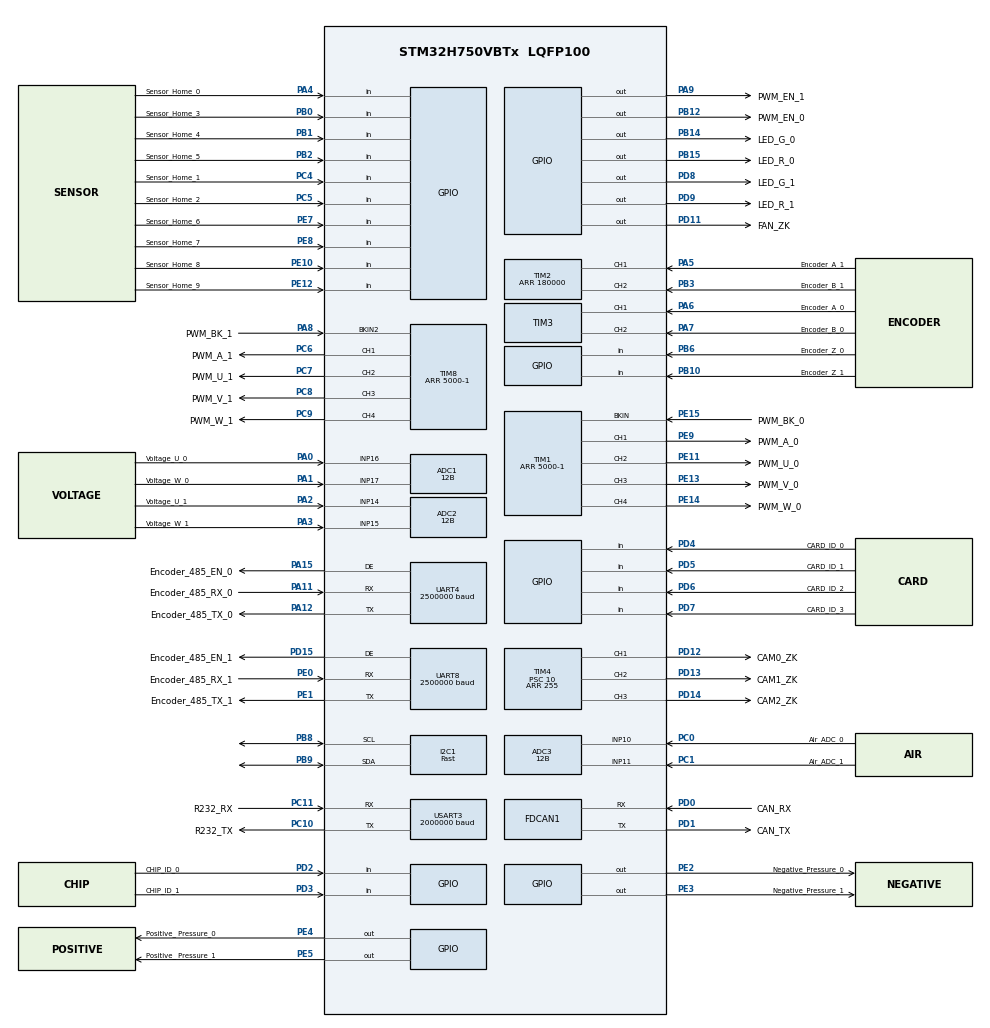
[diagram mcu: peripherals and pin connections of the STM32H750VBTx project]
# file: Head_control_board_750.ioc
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ADC1.EOCSelection=ADC_EOC_SEQ_CONV
ADC1.EnableInjectedConversion=ENABLE
ADC1.EnableRegularConversion=DISABLE
ADC1.ExternalTrigInjecConv=ADC_EXTERNALTRIGINJEC_T1_TRGO
ADC1.InjNumberOfConversion=2
ADC1.InjectedChannel-2\#ChannelInjectedConversion=ADC_CHANNEL_16
ADC1.InjectedChannel-3\#ChannelInjectedConversion=ADC_CHANNEL_17
ADC1.InjectedOffsetNumber-2\#ChannelInjectedConversion=ADC_OFFSET_NONE
ADC1.InjectedOffsetNumber-3\#ChannelInjectedConversion=ADC_OFFSET_NONE
ADC1.InjectedOffsetSaturation-2\#ChannelInjectedConversion=DISABLE
ADC1.InjectedOffsetSaturation-3\#ChannelInjectedConversion=DISABLE
ADC1.InjectedRank-2\#ChannelInjectedConversion=1
ADC1.InjectedRank-3\#ChannelInjectedConversion=2
ADC1.InjectedSamplingTime-2\#ChannelInjectedConversion=ADC_SAMPLETIME_2CYCLES_5
ADC1.InjectedSamplingTime-3\#ChannelInjectedConversion=ADC_SAMPLETIME_2CYCLES_5
ADC1.Resolution=ADC_RESOLUTION_12B
ADC1.master=1
ADC2.EOCSelection=ADC_EOC_SEQ_CONV
ADC2.EnableInjectedConversion=ENABLE
ADC2.EnableRegularConversion=DISABLE
ADC2.ExternalTrigInjecConv=ADC_EXTERNALTRIGINJEC_T8_TRGO
ADC2.InjNumberOfConversion=2
ADC2.InjectedChannel-3\#ChannelInjectedConversion=ADC_CHANNEL_14
ADC2.InjectedChannel-4\#ChannelInjectedConversion=ADC_CHANNEL_15
ADC2.InjectedOffsetNumber-3\#ChannelInjectedConversion=ADC_OFFSET_NONE
ADC2.InjectedOffsetNumber-4\#ChannelInjectedConversion=ADC_OFFSET_NONE
ADC2.InjectedOffsetSaturation-3\#ChannelInjectedConversion=DISABLE
ADC2.InjectedOffsetSaturation-4\#ChannelInjectedConversion=DISABLE
ADC2.InjectedRank-3\#ChannelInjectedConversion=1
ADC2.InjectedRank-4\#ChannelInjectedConversion=2
ADC2.InjectedSamplingTime-3\#ChannelInjectedConversion=ADC_SAMPLETIME_2CYCLES_5
ADC2.InjectedSamplingTime-4\#ChannelInjectedConversion=ADC_SAMPLETIME_2CYCLES_5
ADC2.Resolution=ADC_RESOLUTION_12B
ADC3.Channel-5\#ChannelRegularConversion=ADC_CHANNEL_10
ADC3.Channel-6\#ChannelRegularConversion=ADC_CHANNEL_11
ADC3.Channel-7\#ChannelRegularConversion=ADC_CHANNEL_TEMPSENSOR
ADC3.ContinuousConvMode=ENABLE
ADC3.ConversionDataManagement=ADC_CONVERSIONDATA_DMA_CIRCULAR
ADC3.EOCSelection=ADC_EOC_SEQ_CONV
ADC3.EnableInjectedConversion=DISABLE
ADC3.EnableRegularConversion=ENABLE
ADC3.NbrOfConversion=3
ADC3.NbrOfConversionFlag=1
ADC3.OffsetNumber-5\#ChannelRegularConversion=ADC_OFFSET_NONE
ADC3.OffsetNumber-6\#ChannelRegularConversion=ADC_OFFSET_NONE
ADC3.OffsetNumber-7\#ChannelRegularConversion=ADC_OFFSET_NONE
ADC3.Rank-5\#ChannelRegularConversion=1
ADC3.Rank-6\#ChannelRegularConversion=2
ADC3.Rank-7\#ChannelRegularConversion=3
ADC3.Resolution=ADC_RESOLUTION_12B
ADC3.SamplingTime-5\#ChannelRegularConversion=ADC_SAMPLETIME_32CYCLES_5
ADC3.SamplingTime-6\#ChannelRegularConversion=ADC_SAMPLETIME_32CYCLES_5
ADC3.SamplingTime-7\#ChannelRegularConversion=ADC_SAMPLETIME_32CYCLES_5
CORTEX_M7.default_mode_Activation=1
Dma.ADC1.3.Direction=DMA_PERIPH_TO_MEMORY
Dma.ADC1.3.EventEnable=DISABLE
Dma.ADC1.3.FIFOMode=DMA_FIFOMODE_DISABLE
Dma.ADC1.3.Instance=DMA1_Stream0
Dma.ADC1.3.MemDataAlignment=DMA_MDATAALIGN_WORD
Dma.ADC1.3.MemInc=DMA_MINC_ENABLE
Dma.ADC1.3.Mode=DMA_CIRCULAR
Dma.ADC1.3.PeriphDataAlignment=DMA_PDATAALIGN_WORD
Dma.ADC1.3.PeriphInc=DMA_PINC_DISABLE
Dma.ADC1.3.Polarity=HAL_DMAMUX_REQ_GEN_RISING
Dma.ADC1.3.Priority=DMA_PRIORITY_LOW
Dma.ADC1.3.RequestNumber=1
Dma.ADC1.3.SignalID=NONE
Dma.ADC1.3.SyncEnable=DISABLE
Dma.ADC1.3.SyncPolarity=HAL_DMAMUX_SYNC_NO_EVENT
Dma.ADC1.3.SyncRequestNumber=1
Dma.ADC1.3.SyncSignalID=NONE
Dma.ADC2.4.Direction=DMA_PERIPH_TO_MEMORY
Dma.ADC2.4.EventEnable=DISABLE
Dma.ADC2.4.FIFOMode=DMA_FIFOMODE_DISABLE
Dma.ADC2.4.Instance=DMA2_Stream0
Dma.ADC2.4.MemDataAlignment=DMA_MDATAALIGN_WORD
Dma.ADC2.4.MemInc=DMA_MINC_ENABLE
Dma.ADC2.4.Mode=DMA_CIRCULAR
Dma.ADC2.4.PeriphDataAlignment=DMA_PDATAALIGN_WORD
Dma.ADC2.4.PeriphInc=DMA_PINC_DISABLE
Dma.ADC2.4.Polarity=HAL_DMAMUX_REQ_GEN_RISING
Dma.ADC2.4.Priority=DMA_PRIORITY_LOW
Dma.ADC2.4.RequestNumber=1
Dma.ADC2.4.SignalID=NONE
Dma.ADC2.4.SyncEnable=DISABLE
Dma.ADC2.4.SyncPolarity=HAL_DMAMUX_SYNC_NO_EVENT
Dma.ADC2.4.SyncRequestNumber=1
Dma.ADC2.4.SyncSignalID=NONE
Dma.ADC3.5.Direction=DMA_PERIPH_TO_MEMORY
Dma.ADC3.5.EventEnable=DISABLE
Dma.ADC3.5.FIFOMode=DMA_FIFOMODE_DISABLE
Dma.ADC3.5.Instance=DMA1_Stream2
Dma.ADC3.5.MemDataAlignment=DMA_MDATAALIGN_HALFWORD
Dma.ADC3.5.MemInc=DMA_MINC_ENABLE
Dma.ADC3.5.Mode=DMA_CIRCULAR
Dma.ADC3.5.PeriphDataAlignment=DMA_PDATAALIGN_HALFWORD
Dma.ADC3.5.PeriphInc=DMA_PINC_DISABLE
Dma.ADC3.5.Polarity=HAL_DMAMUX_REQ_GEN_RISING
Dma.ADC3.5.Priority=DMA_PRIORITY_LOW
Dma.ADC3.5.RequestNumber=1
Dma.ADC3.5.SignalID=NONE
Dma.ADC3.5.SyncEnable=DISABLE
Dma.ADC3.5.SyncPolarity=HAL_DMAMUX_SYNC_NO_EVENT
Dma.ADC3.5.SyncRequestNumber=1
Dma.ADC3.5.SyncSignalID=NONE
Dma.I2C1_RX.9.Direction=DMA_PERIPH_TO_MEMORY
Dma.I2C1_RX.9.EventEnable=DISABLE
Dma.I2C1_RX.9.FIFOMode=DMA_FIFOMODE_DISABLE
Dma.I2C1_RX.9.Instance=DMA1_Stream7
Dma.I2C1_RX.9.MemDataAlignment=DMA_MDATAALIGN_BYTE
Dma.I2C1_RX.9.MemInc=DMA_MINC_ENABLE
Dma.I2C1_RX.9.Mode=DMA_NORMAL
Dma.I2C1_RX.9.PeriphDataAlignment=DMA_PDATAALIGN_BYTE
Dma.I2C1_RX.9.PeriphInc=DMA_PINC_DISABLE
Dma.I2C1_RX.9.Polarity=HAL_DMAMUX_REQ_GEN_RISING
Dma.I2C1_RX.9.Priority=DMA_PRIORITY_LOW
Dma.I2C1_RX.9.RequestNumber=1
Dma.I2C1_RX.9.SignalID=NONE
Dma.I2C1_RX.9.SyncEnable=DISABLE
Dma.I2C1_RX.9.SyncPolarity=HAL_DMAMUX_SYNC_NO_EVENT
Dma.I2C1_RX.9.SyncRequestNumber=1
Dma.I2C1_RX.9.SyncSignalID=NONE
Dma.I2C1_TX.10.Direction=DMA_MEMORY_TO_PERIPH
Dma.I2C1_TX.10.EventEnable=DISABLE
Dma.I2C1_TX.10.FIFOMode=DMA_FIFOMODE_DISABLE
Dma.I2C1_TX.10.Instance=DMA2_Stream1
Dma.I2C1_TX.10.MemDataAlignment=DMA_MDATAALIGN_BYTE
Dma.I2C1_TX.10.MemInc=DMA_MINC_ENABLE
Dma.I2C1_TX.10.Mode=DMA_NORMAL
Dma.I2C1_TX.10.PeriphDataAlignment=DMA_PDATAALIGN_BYTE
Dma.I2C1_TX.10.PeriphInc=DMA_PINC_DISABLE
Dma.I2C1_TX.10.Polarity=HAL_DMAMUX_REQ_GEN_RISING
Dma.I2C1_TX.10.Priority=DMA_PRIORITY_LOW
Dma.I2C1_TX.10.RequestNumber=1
Dma.I2C1_TX.10.SignalID=NONE
Dma.I2C1_TX.10.SyncEnable=DISABLE
Dma.I2C1_TX.10.SyncPolarity=HAL_DMAMUX_SYNC_NO_EVENT
Dma.I2C1_TX.10.SyncRequestNumber=1
Dma.I2C1_TX.10.SyncSignalID=NONE
Dma.Request0=USART3_RX
Dma.Request1=USART3_TX
Dma.Request10=I2C1_TX
Dma.Request2=UART4_RX
Dma.Request3=ADC1
Dma.Request4=ADC2
Dma.Request5=ADC3
Dma.Request6=UART4_TX
Dma.Request7=UART8_RX
Dma.Request8=UART8_TX
Dma.Request9=I2C1_RX
Dma.UART4_RX.2.Direction=DMA_PERIPH_TO_MEMORY
Dma.UART4_RX.2.EventEnable=DISABLE
Dma.UART4_RX.2.FIFOMode=DMA_FIFOMODE_DISABLE
Dma.UART4_RX.2.Instance=DMA2_Stream4
Dma.UART4_RX.2.MemDataAlignment=DMA_MDATAALIGN_BYTE
Dma.UART4_RX.2.MemInc=DMA_MINC_ENABLE
Dma.UART4_RX.2.Mode=DMA_NORMAL
Dma.UART4_RX.2.PeriphDataAlignment=DMA_PDATAALIGN_BYTE
Dma.UART4_RX.2.PeriphInc=DMA_PINC_DISABLE
Dma.UART4_RX.2.Polarity=HAL_DMAMUX_REQ_GEN_RISING
Dma.UART4_RX.2.Priority=DMA_PRIORITY_LOW
Dma.UART4_RX.2.RequestNumber=1
Dma.UART4_RX.2.SignalID=NONE
Dma.UART4_RX.2.SyncEnable=DISABLE
Dma.UART4_RX.2.SyncPolarity=HAL_DMAMUX_SYNC_NO_EVENT
Dma.UART4_RX.2.SyncRequestNumber=1
Dma.UART4_RX.2.SyncSignalID=NONE
Dma.UART4_TX.6.Direction=DMA_MEMORY_TO_PERIPH
Dma.UART4_TX.6.EventEnable=DISABLE
Dma.UART4_TX.6.FIFOMode=DMA_FIFOMODE_DISABLE
Dma.UART4_TX.6.Instance=DMA1_Stream4
Dma.UART4_TX.6.MemDataAlignment=DMA_MDATAALIGN_BYTE
Dma.UART4_TX.6.MemInc=DMA_MINC_ENABLE
Dma.UART4_TX.6.Mode=DMA_NORMAL
Dma.UART4_TX.6.PeriphDataAlignment=DMA_PDATAALIGN_BYTE
Dma.UART4_TX.6.PeriphInc=DMA_PINC_DISABLE
Dma.UART4_TX.6.Polarity=HAL_DMAMUX_REQ_GEN_RISING
Dma.UART4_TX.6.Priority=DMA_PRIORITY_LOW
Dma.UART4_TX.6.RequestNumber=1
Dma.UART4_TX.6.SignalID=NONE
Dma.UART4_TX.6.SyncEnable=DISABLE
Dma.UART4_TX.6.SyncPolarity=HAL_DMAMUX_SYNC_NO_EVENT
Dma.UART4_TX.6.SyncRequestNumber=1
Dma.UART4_TX.6.SyncSignalID=NONE
Dma.UART8_RX.7.Direction=DMA_PERIPH_TO_MEMORY
Dma.UART8_RX.7.EventEnable=DISABLE
Dma.UART8_RX.7.FIFOMode=DMA_FIFOMODE_DISABLE
Dma.UART8_RX.7.Instance=DMA1_Stream5
Dma.UART8_RX.7.MemDataAlignment=DMA_MDATAALIGN_BYTE
Dma.UART8_RX.7.MemInc=DMA_MINC_ENABLE
Dma.UART8_RX.7.Mode=DMA_NORMAL
Dma.UART8_RX.7.PeriphDataAlignment=DMA_PDATAALIGN_BYTE
Dma.UART8_RX.7.PeriphInc=DMA_PINC_DISABLE
Dma.UART8_RX.7.Polarity=HAL_DMAMUX_REQ_GEN_RISING
Dma.UART8_RX.7.Priority=DMA_PRIORITY_LOW
Dma.UART8_RX.7.RequestNumber=1
Dma.UART8_RX.7.SignalID=NONE
Dma.UART8_RX.7.SyncEnable=DISABLE
Dma.UART8_RX.7.SyncPolarity=HAL_DMAMUX_SYNC_NO_EVENT
Dma.UART8_RX.7.SyncRequestNumber=1
Dma.UART8_RX.7.SyncSignalID=NONE
Dma.UART8_TX.8.Direction=DMA_MEMORY_TO_PERIPH
Dma.UART8_TX.8.EventEnable=DISABLE
Dma.UART8_TX.8.FIFOMode=DMA_FIFOMODE_DISABLE
Dma.UART8_TX.8.Instance=DMA1_Stream6
Dma.UART8_TX.8.MemDataAlignment=DMA_MDATAALIGN_BYTE
Dma.UART8_TX.8.MemInc=DMA_MINC_ENABLE
Dma.UART8_TX.8.Mode=DMA_NORMAL
Dma.UART8_TX.8.PeriphDataAlignment=DMA_PDATAALIGN_BYTE
Dma.UART8_TX.8.PeriphInc=DMA_PINC_DISABLE
Dma.UART8_TX.8.Polarity=HAL_DMAMUX_REQ_GEN_RISING
Dma.UART8_TX.8.Priority=DMA_PRIORITY_LOW
Dma.UART8_TX.8.RequestNumber=1
Dma.UART8_TX.8.SignalID=NONE
Dma.UART8_TX.8.SyncEnable=DISABLE
Dma.UART8_TX.8.SyncPolarity=HAL_DMAMUX_SYNC_NO_EVENT
Dma.UART8_TX.8.SyncRequestNumber=1
Dma.UART8_TX.8.SyncSignalID=NONE
Dma.USART3_RX.0.Direction=DMA_PERIPH_TO_MEMORY
Dma.USART3_RX.0.EventEnable=DISABLE
Dma.USART3_RX.0.FIFOMode=DMA_FIFOMODE_DISABLE
Dma.USART3_RX.0.Instance=DMA1_Stream1
Dma.USART3_RX.0.MemDataAlignment=DMA_MDATAALIGN_BYTE
Dma.USART3_RX.0.MemInc=DMA_MINC_ENABLE
Dma.USART3_RX.0.Mode=DMA_NORMAL
Dma.USART3_RX.0.PeriphDataAlignment=DMA_PDATAALIGN_BYTE
Dma.USART3_RX.0.PeriphInc=DMA_PINC_DISABLE
Dma.USART3_RX.0.Polarity=HAL_DMAMUX_REQ_GEN_RISING
Dma.USART3_RX.0.Priority=DMA_PRIORITY_LOW
Dma.USART3_RX.0.RequestNumber=1
Dma.USART3_RX.0.SignalID=NONE
Dma.USART3_RX.0.SyncEnable=DISABLE
Dma.USART3_RX.0.SyncPolarity=HAL_DMAMUX_SYNC_NO_EVENT
Dma.USART3_RX.0.SyncRequestNumber=1
Dma.USART3_RX.0.SyncSignalID=NONE
Dma.USART3_TX.1.Direction=DMA_MEMORY_TO_PERIPH
Dma.USART3_TX.1.EventEnable=DISABLE
Dma.USART3_TX.1.FIFOMode=DMA_FIFOMODE_DISABLE
Dma.USART3_TX.1.Instance=DMA1_Stream3
Dma.USART3_TX.1.MemDataAlignment=DMA_MDATAALIGN_BYTE
Dma.USART3_TX.1.MemInc=DMA_MINC_ENABLE
Dma.USART3_TX.1.Mode=DMA_NORMAL
Dma.USART3_TX.1.PeriphDataAlignment=DMA_PDATAALIGN_BYTE
Dma.USART3_TX.1.PeriphInc=DMA_PINC_DISABLE
Dma.USART3_TX.1.Polarity=HAL_DMAMUX_REQ_GEN_RISING
Dma.USART3_TX.1.Priority=DMA_PRIORITY_LOW
Dma.USART3_TX.1.RequestNumber=1
Dma.USART3_TX.1.SignalID=NONE
Dma.USART3_TX.1.SyncEnable=DISABLE
Dma.USART3_TX.1.SyncPolarity=HAL_DMAMUX_SYNC_NO_EVENT
Dma.USART3_TX.1.SyncRequestNumber=1
Dma.USART3_TX.1.SyncSignalID=NONE
FDCAN1.CalculateBaudRateNominal=1000000
FDCAN1.CalculateTimeBitNominal=1000
FDCAN1.CalculateTimeQuantumNominal=100.0
FDCAN1.ExtFiltersNbr=1
FDCAN1.NominalPrescaler=10
FDCAN1.NominalSyncJumpWidth=3
FDCAN1.NominalTimeSeg1=6
FDCAN1.NominalTimeSeg2=3
FDCAN1.RxFifo0ElmtsNbr=1
FDCAN1.TxFifoQueueElmtsNbr=1
I2C1.I2C_Speed_Mode=I2C_Fast
I2C1.Timing=0x009034B6
Mcu.Family=STM32H7
Mcu.Name=STM32H750VBTx
Mcu.Package=LQFP100
NVIC.ADC3_IRQn=true\:0\:0\:false\:false\:true\:true\:true\:true
NVIC.ADC_IRQn=true\:0\:0\:false\:false\:true\:true\:true\:true
NVIC.DMA1_Stream0_IRQn=true\:0\:0\:false\:false\:true\:false\:true\:true
NVIC.DMA1_Stream1_IRQn=true\:0\:0\:false\:false\:true\:false\:true\:true
NVIC.DMA1_Stream2_IRQn=true\:1\:0\:true\:false\:true\:false\:true\:true
NVIC.DMA1_Stream3_IRQn=true\:0\:0\:false\:false\:true\:false\:true\:true
NVIC.DMA1_Stream4_IRQn=true\:0\:0\:false\:false\:true\:false\:true\:true
NVIC.DMA1_Stream5_IRQn=true\:0\:0\:false\:false\:true\:false\:true\:true
NVIC.DMA1_Stream6_IRQn=true\:0\:0\:false\:false\:true\:false\:true\:true
NVIC.DMA1_Stream7_IRQn=true\:0\:0\:false\:false\:true\:false\:true\:true
NVIC.DMA2_Stream0_IRQn=true\:0\:0\:false\:false\:true\:false\:true\:true
NVIC.DMA2_Stream1_IRQn=true\:0\:0\:false\:false\:true\:false\:true\:true
NVIC.DMA2_Stream4_IRQn=true\:0\:0\:false\:false\:true\:false\:true\:true
NVIC.FDCAN1_IT0_IRQn=true\:0\:0\:false\:false\:true\:true\:true\:true
NVIC.PriorityGroup=NVIC_PRIORITYGROUP_4
NVIC.TIM1_BRK_IRQn=true\:0\:0\:false\:false\:true\:true\:true\:true
NVIC.TIM1_UP_IRQn=true\:0\:0\:false\:false\:true\:true\:true\:true
NVIC.TIM2_IRQn=true\:0\:0\:false\:false\:true\:true\:true\:true
NVIC.TIM3_IRQn=true\:0\:0\:false\:false\:true\:true\:true\:true
NVIC.TIM8_BRK_TIM12_IRQn=true\:0\:0\:false\:false\:true\:true\:true\:true
NVIC.TIM8_UP_TIM13_IRQn=true\:0\:0\:false\:false\:true\:true\:true\:true
NVIC.USART3_IRQn=true\:0\:0\:false\:false\:true\:true\:true\:true
PA0.GPIO_Label=Voltage_U_0
PA0.Mode=IN16-Single-Ended
PA0.Signal=ADC1_INP16
PA1.GPIO_Label=Voltage_W_0
PA1.Mode=IN17-Single-Ended
PA1.Signal=ADC1_INP17
PA11.GPIO_Label=Encoder_485_RX_0
PA11.GPIO_Speed=GPIO_SPEED_FREQ_VERY_HIGH
PA11.Mode=Asynchronous
PA11.Signal=UART4_RX
PA12.GPIO_Label=Encoder_485_TX_0
PA12.GPIO_Speed=GPIO_SPEED_FREQ_VERY_HIGH
PA12.Mode=Asynchronous
PA12.Signal=UART4_TX
PA13\ (JTMS/SWDIO).Mode=Serial_Wire
PA13\ (JTMS/SWDIO).Signal=DEBUG_JTMS-SWDIO
PA14\ (JTCK/SWCLK).Mode=Serial_Wire
PA14\ (JTCK/SWCLK).Signal=DEBUG_JTCK-SWCLK
PA15\ (JTDI).GPIO_Label=Encoder_485_EN_0
PA15\ (JTDI).GPIO_Speed=GPIO_SPEED_FREQ_VERY_HIGH
PA15\ (JTDI).Mode=Hardware Flow Control (RS485)
PA15\ (JTDI).Signal=UART4_DE
PA2.GPIO_Label=Voltage_U_1
PA2.Signal=ADCx_INP14
PA3.GPIO_Label=Voltage_W_1
PA3.Signal=ADCx_INP15
PA4.GPIO_Label=Sensor_Home_0
PA4.GPIO_Mode=GPIO_MODE_INPUT
PA4.GPIO_PuPd=GPIO_PULLUP
PA4.Signal=GPIO_Input
PA5.GPIO_Label=Encoder_A_1
PA5.Signal=S_TIM2_CH1_ETR
PA6.GPIO_Label=Encoder_A_0
PA6.Signal=S_TIM3_CH1
PA7.GPIO_Label=Encoder_B_0
PA7.Signal=S_TIM3_CH2
PA8.GPIO_Label=PWM_BK_1
PA8.GPIO_PuPd=GPIO_NOPULL
PA8.Mode=Activate-Break-Input-2
PA8.Signal=TIM8_BKIN2
PA9.GPIO_Label=PWM_EN_1
PA9.GPIO_ModeDefaultOutputPP=GPIO_MODE_OUTPUT_PP
PA9.GPIO_PuPd=GPIO_PULLUP
PA9.GPIO_Speed=GPIO_SPEED_FREQ_LOW
PA9.PinState=GPIO_PIN_RESET
PA9.Signal=GPIO_Output
PB0.GPIO_Label=Sensor_Home_3
PB0.GPIO_Mode=GPIO_MODE_INPUT
PB0.GPIO_PuPd=GPIO_PULLUP
PB0.Signal=GPIO_Input
PB1.GPIO_Label=Sensor_Home_4
PB1.GPIO_Mode=GPIO_MODE_INPUT
PB1.GPIO_PuPd=GPIO_PULLUP
PB1.Signal=GPIO_Input
PB10.GPIO_Label=Encoder_Z_1
PB10.GPIO_Mode=GPIO_MODE_INPUT
PB10.GPIO_PuPd=GPIO_PULLUP
PB10.Signal=GPIO_Input
PB12.GPIO_Label=PWM_EN_0
PB12.GPIO_ModeDefaultOutputPP=GPIO_MODE_OUTPUT_PP
PB12.GPIO_PuPd=GPIO_PULLUP
PB12.GPIO_Speed=GPIO_SPEED_FREQ_LOW
PB12.PinState=GPIO_PIN_RESET
PB12.Signal=GPIO_Output
PB14.GPIO_Label=LED_G_0
PB14.Signal=GPIO_Output
PB15.GPIO_Label=LED_R_0
PB15.Signal=GPIO_Output
PB2.GPIO_Label=Sensor_Home_5
PB2.GPIO_Mode=GPIO_MODE_INPUT
PB2.GPIO_PuPd=GPIO_PULLUP
PB2.Signal=GPIO_Input
PB3\ (JTDO/TRACESWO).GPIO_Label=Encoder_B_1
PB3\ (JTDO/TRACESWO).Signal=S_TIM2_CH2
PB6.GPIO_Label=Encoder_Z_0
PB6.GPIO_Mode=GPIO_MODE_INPUT
PB6.GPIO_PuPd=GPIO_PULLUP
PB6.Signal=GPIO_Input
PB8.Mode=I2C
PB8.Signal=I2C1_SCL
PB9.Mode=I2C
PB9.Signal=I2C1_SDA
PC0.GPIO_Label=Air_ADC_0
PC0.Signal=ADCx_INP10
PC1.GPIO_Label=Air_ADC_1
PC1.Signal=ADCx_INP11
PC10.GPIO_Label=R232_TX
PC10.GPIO_Speed=GPIO_SPEED_FREQ_VERY_HIGH
PC10.Mode=Asynchronous
PC10.Signal=USART3_TX
PC11.GPIO_Label=R232_RX
PC11.GPIO_Speed=GPIO_SPEED_FREQ_VERY_HIGH
PC11.Mode=Asynchronous
PC11.Signal=USART3_RX
PC4.GPIO_Label=Sensor_Home_1
PC4.GPIO_Mode=GPIO_MODE_INPUT
PC4.GPIO_PuPd=GPIO_PULLUP
PC4.Signal=GPIO_Input
PC5.GPIO_Label=Sensor_Home_2
PC5.GPIO_Mode=GPIO_MODE_INPUT
PC5.GPIO_PuPd=GPIO_PULLUP
PC5.Signal=GPIO_Input
PC6.GPIO_Label=PWM_A_1
PC6.Signal=S_TIM8_CH1
PC7.GPIO_Label=PWM_U_1
PC7.Signal=S_TIM8_CH2
PC8.GPIO_Label=PWM_V_1
PC8.Signal=S_TIM8_CH3
PC9.GPIO_Label=PWM_W_1
PC9.Signal=S_TIM8_CH4
PD0.GPIO_Label=CAN_RX
PD0.Mode=FDCAN_Activate
PD0.Signal=FDCAN1_RX
PD1.GPIO_Label=CAN_TX
PD1.Mode=FDCAN_Activate
PD1.Signal=FDCAN1_TX
PD11.GPIO_Label=FAN_ZK
PD11.GPIO_PuPd=GPIO_PULLUP
PD11.Signal=GPIO_Output
PD12.GPIO_Label=CAM0_ZK
PD12.Signal=S_TIM4_CH1
PD13.GPIO_Label=CAM1_ZK
PD13.Signal=S_TIM4_CH2
PD14.GPIO_Label=CAM2_ZK
PD14.Signal=S_TIM4_CH3
PD15.GPIO_Label=Encoder_485_EN_1
PD15.GPIO_Speed=GPIO_SPEED_FREQ_VERY_HIGH
PD15.Mode=Hardware Flow Control (RS485)
PD15.Signal=UART8_DE
PD2.GPIO_Label=CHIP_ID_0
PD2.GPIO_PuPd=GPIO_PULLUP
PD2.Signal=GPIO_Input
PD3.GPIO_Label=CHIP_ID_1
PD3.GPIO_PuPd=GPIO_PULLUP
PD3.Signal=GPIO_Input
PD4.GPIO_Label=CARD_ID_0
PD4.GPIO_PuPd=GPIO_PULLUP
PD4.Signal=GPIO_Input
PD5.GPIO_Label=CARD_ID_1
PD5.GPIO_PuPd=GPIO_PULLUP
PD5.Signal=GPIO_Input
PD6.GPIO_Label=CARD_ID_2
PD6.GPIO_PuPd=GPIO_PULLUP
PD6.Signal=GPIO_Input
PD7.GPIO_Label=CARD_ID_3
PD7.GPIO_PuPd=GPIO_PULLUP
PD7.Signal=GPIO_Input
PD8.GPIO_Label=LED_G_1
PD8.Signal=GPIO_Output
PD9.GPIO_Label=LED_R_1
PD9.GPIO_PuPd=GPIO_NOPULL
PD9.Signal=GPIO_Output
PE0.GPIO_Label=Encoder_485_RX_1
PE0.GPIO_Speed=GPIO_SPEED_FREQ_VERY_HIGH
PE0.Mode=Asynchronous
PE0.Signal=UART8_RX
PE1.GPIO_Label=Encoder_485_TX_1
PE1.GPIO_Speed=GPIO_SPEED_FREQ_VERY_HIGH
PE1.Mode=Asynchronous
PE1.Signal=UART8_TX
PE10.GPIO_Label=Sensor_Home_8
PE10.GPIO_Mode=GPIO_MODE_INPUT
PE10.GPIO_PuPd=GPIO_PULLUP
PE10.Signal=GPIO_Input
PE11.GPIO_Label=PWM_U_0
PE11.Signal=S_TIM1_CH2
PE12.GPIO_Label=Sensor_Home_9
PE12.GPIO_Mode=GPIO_MODE_INPUT
PE12.GPIO_PuPd=GPIO_PULLUP
PE12.Signal=GPIO_Input
PE13.GPIO_Label=PWM_V_0
PE13.Signal=S_TIM1_CH3
PE14.GPIO_Label=PWM_W_0
PE14.Signal=S_TIM1_CH4
PE15.GPIO_Label=PWM_BK_0
PE15.GPIO_Mode=GPIO_MODE_AF_OD
PE15.GPIO_PuPd=GPIO_NOPULL
PE15.Mode=Activate-Break-Input
PE15.Signal=TIM1_BKIN
PE2.GPIO_Label=Negative_Pressure_0
PE2.GPIO_ModeDefaultOutputPP=GPIO_MODE_OUTPUT_PP
PE2.GPIO_PuPd=GPIO_PULLUP
PE2.GPIO_Speed=GPIO_SPEED_FREQ_LOW
PE2.PinState=GPIO_PIN_RESET
PE2.Signal=GPIO_Output
PE3.GPIO_Label=Negative_Pressure_1
PE3.GPIO_ModeDefaultOutputPP=GPIO_MODE_OUTPUT_PP
PE3.GPIO_PuPd=GPIO_PULLUP
PE3.GPIO_Speed=GPIO_SPEED_FREQ_LOW
PE3.PinState=GPIO_PIN_RESET
PE3.Signal=GPIO_Output
PE4.GPIO_Label=Positive_ Pressure_0
PE4.GPIO_ModeDefaultOutputPP=GPIO_MODE_OUTPUT_PP
PE4.GPIO_PuPd=GPIO_PULLUP
PE4.GPIO_Speed=GPIO_SPEED_FREQ_LOW
PE4.PinState=GPIO_PIN_RESET
PE4.Signal=GPIO_Output
PE5.GPIO_Label=Positive_ Pressure_1
PE5.GPIO_ModeDefaultOutputPP=GPIO_MODE_OUTPUT_PP
PE5.GPIO_PuPd=GPIO_PULLUP
PE5.GPIO_Speed=GPIO_SPEED_FREQ_LOW
PE5.PinState=GPIO_PIN_RESET
PE5.Signal=GPIO_Output
PE7.GPIO_Label=Sensor_Home_6
PE7.GPIO_Mode=GPIO_MODE_INPUT
PE7.GPIO_PuPd=GPIO_PULLUP
PE7.Signal=GPIO_Input
PE8.GPIO_Label=Sensor_Home_7
PE8.GPIO_Mode=GPIO_MODE_INPUT
PE8.GPIO_PuPd=GPIO_PULLUP
PE8.Signal=GPIO_Input
PE9.GPIO_Label=PWM_A_0
PE9.Signal=S_TIM1_CH1
PH0-OSC_IN\ (PH0).Mode=HSE-External-Clock-Source
PH0-OSC_IN\ (PH0).Signal=RCC_OSC_IN
ProjectManager.HeapSize=0x200
ProjectManager.StackSize=0x400
ProjectManager.TargetToolchain=CMake
RCC.ADCFreq_Value=100000000
RCC.APB1Freq_Value=100000000
RCC.APB2Freq_Value=100000000
RCC.APB3Freq_Value=100000000
RCC.APB4Freq_Value=100000000
RCC.CortexFreq_Value=400000000
RCC.D1PPRE=RCC_APB3_DIV2
RCC.D2PPRE1=RCC_APB1_DIV2
RCC.D2PPRE2=RCC_APB2_DIV2
RCC.D3PPRE=RCC_APB4_DIV2
RCC.DIVM1=5
RCC.DIVM2=5
RCC.DIVN1=160
RCC.DIVN2=160
RCC.DIVP2=8
RCC.DIVQ1=8
RCC.HCLKFreq_Value=200000000
RCC.HPRE=RCC_HCLK_DIV2
RCC.PLLSourceVirtual=RCC_PLLSOURCE_HSE
RCC.SYSCLKFreq_VALUE=400000000
RCC.SYSCLKSource=RCC_SYSCLKSOURCE_PLLCLK
RCC.USBFreq_Value=100000000
SH.ADCx_INP10.0=ADC3_INP10,IN10-Single-Ended
SH.ADCx_INP11.0=ADC3_INP11,IN11-Single-Ended
SH.ADCx_INP14.0=ADC2_INP14,IN14-Single-Ended
SH.ADCx_INP15.0=ADC2_INP15,IN15-Single-Ended
SH.S_TIM1_CH1.0=TIM1_CH1,PWM Generation1 CH1
SH.S_TIM1_CH2.0=TIM1_CH2,PWM Generation2 CH2
SH.S_TIM1_CH3.0=TIM1_CH3,PWM Generation3 CH3
SH.S_TIM1_CH4.0=TIM1_CH4,PWM Generation4 CH4
SH.S_TIM2_CH1_ETR.0=TIM2_CH1,Encoder_Interface
SH.S_TIM2_CH2.0=TIM2_CH2,Encoder_Interface
SH.S_TIM3_CH1.0=TIM3_CH1,Encoder_Interface
SH.S_TIM3_CH2.0=TIM3_CH2,Encoder_Interface
SH.S_TIM4_CH1.0=TIM4_CH1,PWM Generation1 CH1
SH.S_TIM4_CH2.0=TIM4_CH2,PWM Generation2 CH2
SH.S_TIM4_CH3.0=TIM4_CH3,PWM Generation3 CH3
SH.S_TIM8_CH1.0=TIM8_CH1,PWM Generation1 CH1
SH.S_TIM8_CH2.0=TIM8_CH2,PWM Generation2 CH2
SH.S_TIM8_CH3.0=TIM8_CH3,PWM Generation3 CH3
SH.S_TIM8_CH4.0=TIM8_CH4,PWM Generation4 CH4
TIM1.AutoReloadPreload=TIM_AUTORELOAD_PRELOAD_ENABLE
TIM1.AutomaticOutput=TIM_AUTOMATICOUTPUT_ENABLE
TIM1.Break2Polarity=TIM_BREAK2POLARITY_HIGH
TIM1.Break2State=TIM_BREAK2_DISABLE
TIM1.BreakPolarity=TIM_BREAKPOLARITY_LOW
TIM1.BreakState=TIM_BREAK_ENABLE
TIM1.Channel-PWM\ Generation1\ CH1=TIM_CHANNEL_1
TIM1.Channel-PWM\ Generation2\ CH2=TIM_CHANNEL_2
TIM1.Channel-PWM\ Generation3\ CH3=TIM_CHANNEL_3
TIM1.Channel-PWM\ Generation4\ CH4=TIM_CHANNEL_4
TIM1.CounterMode=TIM_COUNTERMODE_CENTERALIGNED3
TIM1.OCMode_PWM-PWM\ Generation1\ CH1=TIM_OCMODE_PWM2
TIM1.OCMode_PWM-PWM\ Generation2\ CH2=TIM_OCMODE_PWM2
TIM1.OCMode_PWM-PWM\ Generation3\ CH3=TIM_OCMODE_PWM2
TIM1.OCMode_PWM-PWM\ Generation4\ CH4=TIM_OCMODE_PWM2
TIM1.OffStateIDLEMode=TIM_OSSI_DISABLE
TIM1.OffStateRunMode=TIM_OSSR_DISABLE
TIM1.Period=5000-1
TIM1.Pulse-PWM\ Generation1\ CH1=0
TIM1.Pulse-PWM\ Generation2\ CH2=0
TIM1.Pulse-PWM\ Generation3\ CH3=0
TIM1.Pulse-PWM\ Generation4\ CH4=0
TIM1.SourceBRKDigInput=TIM_BREAKINPUTSOURCE_DISABLE
TIM1.TIM_MasterOutputTrigger=TIM_TRGO_UPDATE
TIM2.EncoderMode=TIM_ENCODERMODE_TI12
TIM2.Period=180000
TIM3.EncoderMode=TIM_ENCODERMODE_TI12
TIM4.AutoReloadPreload=TIM_AUTORELOAD_PRELOAD_ENABLE
TIM4.Channel-PWM\ Generation1\ CH1=TIM_CHANNEL_1
TIM4.Channel-PWM\ Generation2\ CH2=TIM_CHANNEL_2
TIM4.Channel-PWM\ Generation3\ CH3=TIM_CHANNEL_3
TIM4.Channel-PWM\ Generation4\ CH4=TIM_CHANNEL_4
TIM4.Period=255
TIM4.Prescaler=10
TIM8.Break2Polarity=TIM_BREAK2POLARITY_LOW
TIM8.BreakPolarity=TIM_BREAKPOLARITY_HIGH
TIM8.BreakState=TIM_BREAK_DISABLE
TIM8.Channel-PWM\ Generation1\ CH1=TIM_CHANNEL_1
TIM8.Channel-PWM\ Generation2\ CH2=TIM_CHANNEL_2
TIM8.Channel-PWM\ Generation3\ CH3=TIM_CHANNEL_3
TIM8.Channel-PWM\ Generation4\ CH4=TIM_CHANNEL_4
TIM8.CounterMode=TIM_COUNTERMODE_CENTERALIGNED3
TIM8.OCMode_PWM-PWM\ Generation1\ CH1=TIM_OCMODE_PWM2
TIM8.OCMode_PWM-PWM\ Generation2\ CH2=TIM_OCMODE_PWM2
TIM8.OCMode_PWM-PWM\ Generation3\ CH3=TIM_OCMODE_PWM2
TIM8.OCMode_PWM-PWM\ Generation4\ CH4=TIM_OCMODE_PWM2
TIM8.Period=5000-1
TIM8.Pulse-PWM\ Generation1\ CH1=0
TIM8.Pulse-PWM\ Generation2\ CH2=0
TIM8.Pulse-PWM\ Generation3\ CH3=0
TIM8.Pulse-PWM\ Generation4\ CH4=0
TIM8.SourceBRK2DigInputPolarity=TIM_BREAKINPUTSOURCE_POLARITY_LOW
TIM8.TIM_MasterOutputTrigger=TIM_TRGO_UPDATE
UART4.BaudRate=2500000
UART8.BaudRate=2500000
USART3.BaudRate=2000000
USART3.SwapParam=ADVFEATURE_SWAP_ENABLE
USART3.VirtualMode-Asynchronous=VM_ASYNC
VP_ADC3_TempSens_Input.Mode=IN-TempSens
VP_MEMORYMAP_VS_MEMORYMAP.Mode=CurAppReg
VP_TIM1_VS_ClockSourceINT.Mode=Internal
VP_TIM4_VS_ClockSourceINT.Mode=Internal
VP_TIM8_VS_ClockSourceINT.Mode=Internal
board=custom

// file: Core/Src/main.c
/* USER CODE BEGIN Header */
/**
  ******************************************************************************
  * @file           : main.c
  * @brief          : Main program body
  ******************************************************************************
  * @attention
  *
  * Copyright (c) 2026 STMicroelectronics.
  * All rights reserved.
  *
  * This software is licensed under terms that can be found in the LICENSE file
  * in the root directory of this software component.
  * If no LICENSE file comes with this software, it is provided AS-IS.
  *
  ******************************************************************************
  */
/* USER CODE END Header */
#include "main.h"
#include "adc.h"
#include "dma.h"
#include "fdcan.h"
#include "i2c.h"
#include "tim.h"
#include "usart.h"
#include "gpio.h"

/* USER CODE BEGIN Includes */
#include "global_control.h"
/* USER CODE END Includes */

void SystemClock_Config(void);
void PeriphCommonClock_Config(void);
static void MPU_Config(void);

int main(void)
{

  /* MPU Configuration--------------------------------------------------------*/
  MPU_Config();

  /* MCU Configuration--------------------------------------------------------*/

  /* Reset of all peripherals, Initializes the Flash interface and the Systick. */
  HAL_Init();

  /* Configure the system clock */
  SystemClock_Config();

  /* Configure the peripherals common clocks */
  PeriphCommonClock_Config();

  /* Initialize all configured peripherals */
  MX_GPIO_Init();
  MX_DMA_Init();
  MX_FDCAN1_Init();
  MX_USART3_UART_Init();
  MX_UART4_Init();
  MX_ADC2_Init();
  MX_ADC3_Init();
  MX_ADC1_Init();
  MX_TIM1_Init();
  MX_TIM2_Init();
  MX_TIM3_Init();
  MX_TIM4_Init();
  MX_TIM8_Init();
  MX_I2C1_Init();
  MX_UART8_Init();
  /* USER CODE BEGIN 2 */
    Global_Init();
  /* USER CODE END 2 */

  /* Infinite loop */
    while (1)
    {

    /* USER CODE BEGIN 3 */
    Global_Loop();
    }
  /* USER CODE END 3 */
}

void SystemClock_Config(void)
{
  RCC_OscInitTypeDef RCC_OscInitStruct = {0};
  RCC_ClkInitTypeDef RCC_ClkInitStruct = {0};

  /** Supply configuration update enable
  */
  HAL_PWREx_ConfigSupply(PWR_LDO_SUPPLY);

  /** Configure the main internal regulator output voltage
  */
  __HAL_PWR_VOLTAGESCALING_CONFIG(PWR_REGULATOR_VOLTAGE_SCALE1);

  while(!__HAL_PWR_GET_FLAG(PWR_FLAG_VOSRDY)) {}

  /** Initializes the RCC Oscillators according to the specified parameters
  * in the RCC_OscInitTypeDef structure.
  */
  RCC_OscInitStruct.OscillatorType = RCC_OSCILLATORTYPE_HSE;
  RCC_OscInitStruct.HSEState = RCC_HSE_BYPASS;
  RCC_OscInitStruct.PLL.PLLState = RCC_PLL_ON;
  RCC_OscInitStruct.PLL.PLLSource = RCC_PLLSOURCE_HSE;
  RCC_OscInitStruct.PLL.PLLM = 5;
  RCC_OscInitStruct.PLL.PLLN = 160;
  RCC_OscInitStruct.PLL.PLLP = 2;
  RCC_OscInitStruct.PLL.PLLQ = 8;
  RCC_OscInitStruct.PLL.PLLR = 2;
  RCC_OscInitStruct.PLL.PLLRGE = RCC_PLL1VCIRANGE_2;
  RCC_OscInitStruct.PLL.PLLVCOSEL = RCC_PLL1VCOWIDE;
  RCC_OscInitStruct.PLL.PLLFRACN = 0;
  if (HAL_RCC_OscConfig(&RCC_OscInitStruct) != HAL_OK)
  {
    Error_Handler();
  }

  /** Initializes the CPU, AHB and APB buses clocks
  */
  RCC_ClkInitStruct.ClockType = RCC_CLOCKTYPE_HCLK|RCC_CLOCKTYPE_SYSCLK
                              |RCC_CLOCKTYPE_PCLK1|RCC_CLOCKTYPE_PCLK2
                              |RCC_CLOCKTYPE_D3PCLK1|RCC_CLOCKTYPE_D1PCLK1;
  RCC_ClkInitStruct.SYSCLKSource = RCC_SYSCLKSOURCE_PLLCLK;
  RCC_ClkInitStruct.SYSCLKDivider = RCC_SYSCLK_DIV1;
  RCC_ClkInitStruct.AHBCLKDivider = RCC_HCLK_DIV2;
  RCC_ClkInitStruct.APB3CLKDivider = RCC_APB3_DIV2;
  RCC_ClkInitStruct.APB1CLKDivider = RCC_APB1_DIV2;
  RCC_ClkInitStruct.APB2CLKDivider = RCC_APB2_DIV2;
  RCC_ClkInitStruct.APB4CLKDivider = RCC_APB4_DIV2;

  if (HAL_RCC_ClockConfig(&RCC_ClkInitStruct, FLASH_LATENCY_2) != HAL_OK)
  {
    Error_Handler();
  }
}

void PeriphCommonClock_Config(void)
{
  RCC_PeriphCLKInitTypeDef PeriphClkInitStruct = {0};

  /** Initializes the peripherals clock
  */
  PeriphClkInitStruct.PeriphClockSelection = RCC_PERIPHCLK_ADC;
  PeriphClkInitStruct.PLL2.PLL2M = 5;
  PeriphClkInitStruct.PLL2.PLL2N = 160;
  PeriphClkInitStruct.PLL2.PLL2P = 8;
  PeriphClkInitStruct.PLL2.PLL2Q = 2;
  PeriphClkInitStruct.PLL2.PLL2R = 2;
  PeriphClkInitStruct.PLL2.PLL2RGE = RCC_PLL2VCIRANGE_2;
  PeriphClkInitStruct.PLL2.PLL2VCOSEL = RCC_PLL2VCOWIDE;
  PeriphClkInitStruct.PLL2.PLL2FRACN = 0;
  PeriphClkInitStruct.AdcClockSelection = RCC_ADCCLKSOURCE_PLL2;
  if (HAL_RCCEx_PeriphCLKConfig(&PeriphClkInitStruct) != HAL_OK)
  {
    Error_Handler();
  }
}

 /* MPU Configuration */

void MPU_Config(void)
{
  MPU_Region_InitTypeDef MPU_InitStruct = {0};

  /* Disables the MPU */
  HAL_MPU_Disable();

  /** Initializes and configures the Region and the memory to be protected
  */
  MPU_InitStruct.Enable = MPU_REGION_ENABLE;
  MPU_InitStruct.Number = MPU_REGION_NUMBER0;
  MPU_InitStruct.BaseAddress = 0x0;
  MPU_InitStruct.Size = MPU_REGION_SIZE_4GB;
  MPU_InitStruct.SubRegionDisable = 0x87;
  MPU_InitStruct.TypeExtField = MPU_TEX_LEVEL0;
  MPU_InitStruct.AccessPermission = MPU_REGION_NO_ACCESS;
  MPU_InitStruct.DisableExec = MPU_INSTRUCTION_ACCESS_DISABLE;
  MPU_InitStruct.IsShareable = MPU_ACCESS_SHAREABLE;
  MPU_InitStruct.IsCacheable = MPU_ACCESS_NOT_CACHEABLE;
  MPU_InitStruct.IsBufferable = MPU_ACCESS_NOT_BUFFERABLE;

  HAL_MPU_ConfigRegion(&MPU_InitStruct);
  /* Enables the MPU */
  HAL_MPU_Enable(MPU_PRIVILEGED_DEFAULT);

}

void Error_Handler(void)
{
    __disable_irq();
    while (1)
    {
    }
}
